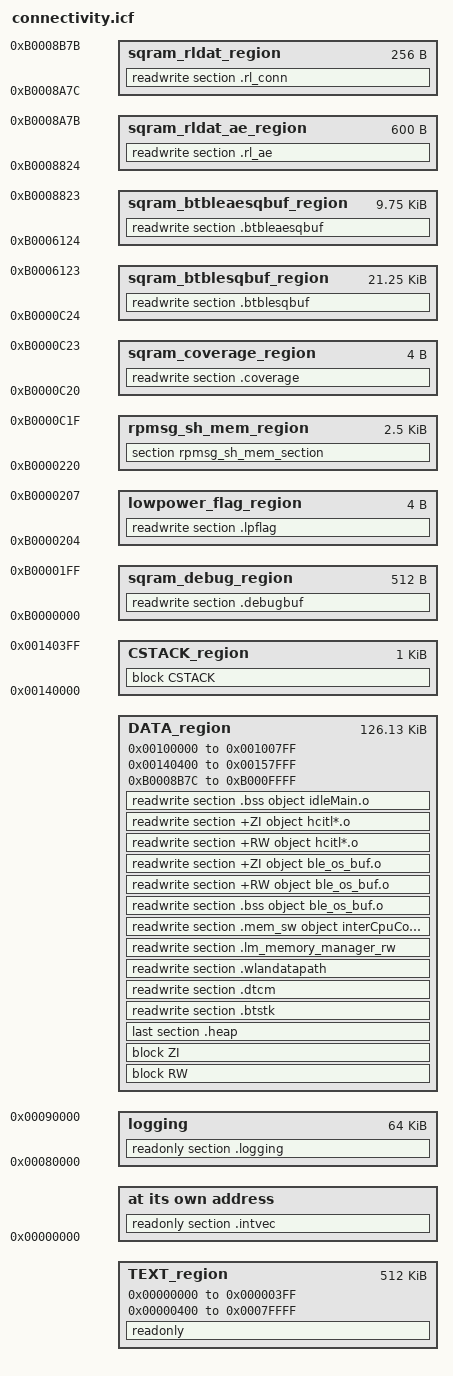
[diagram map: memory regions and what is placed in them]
/*
** ###################################################################
**     Processors:          KW47B42Z83AFTA_cm33_core1
**                          KW47B42Z96FTA_cm33_core1
**                          KW47B42Z97AFTA_cm33_core1
**                          KW47B42ZB2AFTA_cm33_core1
**                          KW47B42ZB3AFTA_cm33_core1
**                          KW47B42ZB6AFTA_cm33_core1
**                          KW47B42ZB7AFTA_cm33_core1
**                          MCXW727CAFTA_cm33_core1
**                          MCXW727AAFTA_cm33_core1
**                          MCXW727DAFTA_cm33_core1
**
**     Compiler:            IAR ANSI C/C++ Compiler for ARM
**     Reference manual:    K32W133G256RM, Rev. 0, Mar 2018
**     Version:             rev. 1.0, 2020-05-12
**     Build:               b200716
**
**     Abstract:
**         Linker file for the IAR ANSI C/C++ Compiler for ARM
**
**     Copyright 2024 NXP
**
**     SPDX-License-Identifier: BSD-3-Clause
**
**     http:                 www.nxp.com
**     mail:                 support@nxp.com
**
** ###################################################################
*/
if (!isdefinedsymbol(gEnableCoverage_d)) {
    define symbol gEnableCoverage_d = 0;
}


/* Stack and Heap Sizes */
if (isdefinedsymbol(__stack_size__)) {
  define symbol __size_cstack__        = __stack_size__;
} else {
  define symbol __size_cstack__        = 0x0400;
}

if (isdefinedsymbol(__heap_size__)) {
  define symbol __size_heap__          = __heap_size__;
} else {
  define symbol __size_heap__          = 0x000;  /*Memory manager is not used. */
}

/* The addition of the SMU size and the DMEM size is a constant but the sharing can change (see SMU_MEM_SEL)*/
define symbol smu_and_dmem_size                = 0x00028000;

/********************************************** NBU shared memory **********************************************

                                            m_shared_ram_end
                    - - - +---------------+ - - - - - - - -
                          |               | m_free_data_end
                          |   free data   |
                          |               |
                          |               | m_free_data_start
                    - - - +---------------+ - - - - - - - -
                          |               | m_sqram_rldat_end
                          |     rldat     |
                          |               |
                          |               | m_sqram_rldat_start
                    - - - +---------------+ - - - - - - - -
                          |               | m_sqram_rldat_ae_end
                          |   rldat_ae    |
                          |               |
                          |               | m_sqram_rldat_ae_start
                    - - - +---------------+ - - - - - - - -
                          |               | m_sqram_btbleaesqbuf_end
                          |  btbleaesqbuf |
                          |               |
                          |               | m_sqram_btbleaesqbuf_start
                    - - - +---------------+ - - - - - - - -
                          |               | m_sqram_btblesqbuf_end
                          |   btblebuf    |
                          |               |
                          |               | m_sqram_btblesqbuf_start
                    - - - +---------------+ - - - - - - - -
                          |               | dbg_ext_logging_end
                          |  DBG logging  |
                          |               |
                          |               | dbg_ext_logging_start
                    - - - +---------------+ - - - - - - - -
                          |               | rpmsg_sh_mem_end
                          |     RPMSG     |
                          |               | rpmsg_sh_mem_start
                    - - - +---------------+ - - - - - - - -
                          |               | framework_info_sh_mem_end
                          |    FWK Info   |
                          |               | framework_info_sh_mem_start
                    - - - +---------------+ - - - - - - - -
                          |               | m_sqram_debug_end
                          |    LL Debug   |
                          |               | m_sqram_debug_start
                    - - - +---------------+ - - - - - - - -
                          |               | m_shared_ram_start
**************************************************************************************************/

/* Do not change shall be aligned with other core firmware */
define exported symbol m_shared_ram_start       = 0xB0000000;
define symbol m_shared_ram_size                 = 0x10000;
define exported symbol m_shared_ram_end         = m_shared_ram_start + m_shared_ram_size - 1;

/* Section allowing to share debug info to CM33 (LL error/warnings).*/
define exported symbol m_sqram_debug_start      = m_shared_ram_start;
define symbol m_sqram_debug_size                = 0x200;
define symbol m_sqram_debug_end                 = m_shared_ram_start + m_sqram_debug_size - 1;

/* Section used to share platform/services (SFC, Lowpower) information on both cores */
define symbol framework_info_sh_mem_start       = m_sqram_debug_end + 1;
define symbol framework_info_sh_mem_size        = 0x20;
define symbol framework_info_sh_mem_end         = framework_info_sh_mem_start + framework_info_sh_mem_size - 1;

/* Section used for the sfc module intercore debug */
define exported symbol m_sfc_log_start          = framework_info_sh_mem_start;
define symbol m_sfc_log_size                    = 0x04;

/* Section used to share a flag on both cores for lowpower purpose */
define exported symbol m_lowpower_flag_start    = framework_info_sh_mem_start + m_sfc_log_size;
define symbol m_lowpower_flag_size              = 0x04;
define symbol m_lowpower_flag_end               = m_lowpower_flag_start + m_lowpower_flag_size - 1;

/* RPMSG section for intercore communication */
define exported symbol rpmsg_sh_mem_size        = 0xA00;
define exported symbol rpmsg_sh_mem_start       = framework_info_sh_mem_end + 1;
define exported symbol rpmsg_sh_mem_end         = rpmsg_sh_mem_start + rpmsg_sh_mem_size - 1;


if (gEnableCoverage_d) {
define exported symbol sh_mem_coverage_size     = 0x4;
define exported symbol sh_mem_coverage_start    = rpmsg_sh_mem_end + 1;
define exported symbol sh_mem_coverage_end      = sh_mem_coverage_start + sh_mem_coverage_size -1;
}

if (gEnableCoverage_d) {
define exported symbol dbg_ext_logging_size     = 0x000;
define exported symbol dbg_ext_logging_start    = sh_mem_coverage_end + 1;
} else {
define exported symbol dbg_ext_logging_size     = 0x1500;
define exported symbol dbg_ext_logging_start    = rpmsg_sh_mem_end + 1;
}
define exported symbol dbg_ext_logging_end      = dbg_ext_logging_start + dbg_ext_logging_size - 1;

define symbol m_sqram_btblesqbuf_start          = dbg_ext_logging_end + 1;
define symbol m_sqram_btblesqbuf_size           = 0x5500;
define symbol m_sqram_btblesqbuf_end            = m_sqram_btblesqbuf_start + m_sqram_btblesqbuf_size - 1;

define symbol m_sqram_btbleaesqbuf_start        = m_sqram_btblesqbuf_end + 1;
define symbol m_sqram_btbleaesqbuf_size         = 0x2700;     /* was 0xF00 but was increased to hold 2 x 3 x 1650 bytes for advertising.*/
define symbol m_sqram_btbleaesqbuf_end          = m_sqram_btbleaesqbuf_start + m_sqram_btbleaesqbuf_size -1;

define symbol m_sqram_rldat_ae_start            = m_sqram_btbleaesqbuf_end + 1;
define symbol m_sqram_rldat_ae_size             = 0x00258;
define symbol m_sqram_rldat_ae_end              = m_sqram_rldat_ae_start + m_sqram_rldat_ae_size -1;

define symbol m_sqram_rldat_start               = m_sqram_rldat_ae_end + 1;
if (gEnableCoverage_d) {
define symbol m_sqram_rldat_size                = 0x00100;
} else {
define symbol m_sqram_rldat_size                = 0x005dc;  /*to hold 24 connection contexts*/
}
define symbol m_sqram_rldat_end                 = m_sqram_rldat_start + m_sqram_rldat_size -1;

define symbol m_free_data_start                 = m_sqram_rldat_end + 1;
define symbol m_free_data_size                  = m_shared_ram_end - m_sqram_rldat_end;
define symbol m_free_data_end                   = m_shared_ram_end;

if (m_sqram_rldat_end > m_shared_ram_end)
{
  error "Total allocated sections in shared ram do not fit in available shared ram!";
}

/* This size can be changed depending on the dmem shared mem muxing chosen (see SMU_MEM_SEL)*/
/*define symbol m_dmem_size                      = 0x00014000;*/  /*80 KB*/
define symbol m_dmem_size                      = smu_and_dmem_size - m_shared_ram_size;  /*96 KB*/
define exported symbol m_dmem_start            = 0x00140000;
define exported symbol m_dmem_end              = m_dmem_start + m_dmem_size - 1;

define symbol m_flash_start                    = 0x00000000;
define symbol m_flash_end                      = 0x0007FFFF;

define symbol m_interrupts_start               = m_flash_start;
define symbol m_interrupts_end                 = 0x000003FF;

define exported symbol m_text_start             = 0x00000400;
define exported symbol m_text_end               = m_flash_end;

define symbol m_data0_start                     = 0x00100000;
define symbol m_data0_end                       = 0x001007FF;

/*Stack moved to the beginning of DMEM to allow for DMEM/SMU memory configuration at runtime.*/
define symbol m_cstack_start                      = 0x00140000;
define exported symbol m_cstack_end               = m_cstack_start + __size_cstack__ - 1;

define symbol m_data1_start                       = m_cstack_end + 1;
define symbol m_data1_end                         = m_dmem_end - __size_heap__;

define exported symbol __HEAP_start__           = m_data1_end + 1;
if (__size_heap__ > 0) {
  define exported symbol __HEAP_end__             = __HEAP_start__ + __size_heap__ - 1;
} else {
  define exported symbol __HEAP_end__             = __HEAP_start__;
}

define memory mem with size = 4G;

define region TEXT_region             = mem:[from m_interrupts_start to m_interrupts_end]
                                      | mem:[from m_text_start to m_text_end];
define region DATA_region             = mem:[from m_data0_start to m_data0_end]
                                      | mem:[from m_data1_start to m_data1_end]
                                      | mem:[from __HEAP_start__ to __HEAP_end__]
                                      | mem:[from m_free_data_start to m_free_data_end];
define region CSTACK_region           = mem:[from m_cstack_start to m_cstack_end];

define region sqram_debug_region                = mem:[from m_sqram_debug_start         to m_sqram_debug_end];
define region lowpower_flag_region              = mem:[from m_lowpower_flag_start       to m_lowpower_flag_end];
define region sqram_btblesqbuf_region           = mem:[from m_sqram_btblesqbuf_start    to m_sqram_btblesqbuf_end];
define region sqram_btbleaesqbuf_region         = mem:[from m_sqram_btbleaesqbuf_start  to m_sqram_btbleaesqbuf_end];
define region sqram_rldat_ae_region             = mem:[from m_sqram_rldat_ae_start      to m_sqram_rldat_ae_end];
define region sqram_rldat_region                = mem:[from m_sqram_rldat_start         to m_sqram_rldat_end];
if (gEnableCoverage_d) {
define region sqram_coverage_region             = mem:[from sh_mem_coverage_start      to sh_mem_coverage_end];
}
define region sqram_dbg_ext_logging_region      = mem:[from dbg_ext_logging_start       to dbg_ext_logging_end];

/* Logging section appended at the end of the nbu binary (not flashed into the device)*/
define symbol logging_start                     = 0x80000;
define symbol logging_end                       = 0x90000;
define region logging                           = mem:[from logging_start               to logging_end];
define region rpmsg_sh_mem_region               = mem:[from rpmsg_sh_mem_start          to rpmsg_sh_mem_end];


define block CSTACK    with alignment = 8, size = __size_cstack__   { };
define block RW        { readwrite };
define block ZI        { zi };

initialize by copy { readwrite, section .textrw };

if (isdefinedsymbol(__USE_DLIB_PERTHREAD))
{
  /* Required in a multi-threaded application */
  initialize by copy with packing = none { section __DLIB_PERTHREAD };
}

do not initialize  { section .noinit };
do not initialize  { section .heap };

place at address mem: m_interrupts_start    { readonly section .intvec };
place in TEXT_region                        { readonly };
place in DATA_region                        { block RW };
place in DATA_region                        { block ZI };
place in DATA_region                        { last section .heap };
place in CSTACK_region                      { block CSTACK };

place in sqram_debug_region                       { readwrite section .debugbuf } ;
place in lowpower_flag_region                     { readwrite section .lpflag } ;
place in sqram_btblesqbuf_region                  { readwrite section .btblesqbuf } ;
place in sqram_btbleaesqbuf_region              { readwrite section .btbleaesqbuf } ;
place in sqram_rldat_ae_region                  { readwrite section .rl_ae } ;
place in sqram_rldat_region                     { readwrite section .rl_conn } ;
place in sqram_dbg_ext_logging_region           { readwrite section .trackbuf } ;
if (gEnableCoverage_d) {
place in sqram_coverage_region                     { readwrite section .coverage } ;
}

place in DATA_region
{
    readwrite section .btstk,
    readwrite section .dtcm,
    readwrite section .wlandatapath,
    readwrite section .lm_memory_manager_rw,
    readwrite section .mem_sw object interCpuComm.o,
    readwrite section .bss object ble_os_buf.o,
    readwrite section +RW object ble_os_buf.o,
    readwrite section +ZI object ble_os_buf.o,
    readwrite section +RW object hcitl*.o,
    readwrite section +ZI object hcitl*.o,
    readwrite section .bss object idleMain.o,
};

place in rpmsg_sh_mem_region                    { section rpmsg_sh_mem_section };

place in  logging    { readonly section .logging };

/*
    INFO: original scatter file used from marvell code:
    helper_scat_fpga_V0.scf
*/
